# R7FA2E307 register map
Vendor: Renesas Electronics Corporation; Series: RA2; File version: 1.20.00
CPU: CM23 r1p0, little endian, MPU, no FPU, VTOR, 2 interrupt priority bits, 32 interrupts
Registers are 8-bit, read-write, reset 0x0 unless marked. A register's access mark holds for its fields unless they carry their own. Offsets are from the block's base; [hi:lo] are bit positions; {n}, {i} and the like mark numbered series.

## ADC120 — 12-bit A/D Converter
Base 0x4005C000
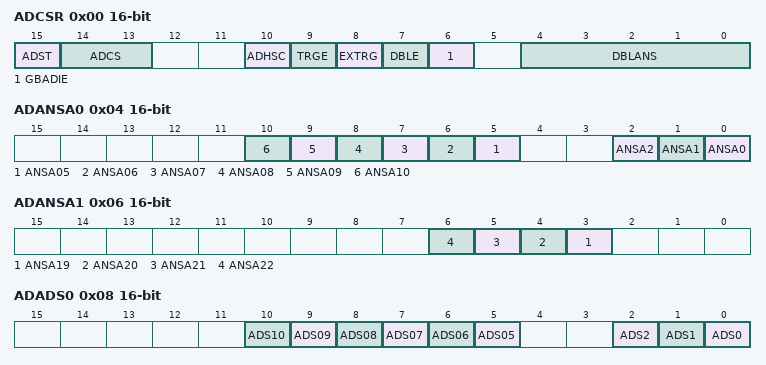
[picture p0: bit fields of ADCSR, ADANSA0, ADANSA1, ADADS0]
0x00 ADCSR 16-bit — A/D Control Register
  [15] ADST — A/D Conversion Start
  [14:13] ADCS — Scan Mode Select
  [10] ADHSC — A/D Conversion Mode Select
  [9] TRGE — Trigger Start Enable
  [8] EXTRG — Trigger Select
  [7] DBLE — Double Trigger Mode Select
  [6] GBADIE — Group B Scan End Interrupt and ELC Event Enable
  [4:0] DBLANS — Double Trigger Channel Select
0x04 ADANSA0 16-bit — A/D Channel Select Register A0
  [n] ANSA{n:02} (n=5..10) — A/D Conversion Channels Select
  [2] ANSA2 — A/D Conversion Channels Select
  [1] ANSA1 — A/D Conversion Channels Select
  [0] ANSA0 — A/D Conversion Channels Select
0x06 ADANSA1 16-bit — A/D Channel Select Register A1
  [n-16] ANSA{n} (n=19..22) — A/D Conversion Channels Select
0x08 ADADS0 16-bit — A/D,Converted Value Addition/Average Channel Select Register 0
  [n] ADS{n:02} (n=5..10) — A/D,Converted Value Addition/Average Channel Select
  [2] ADS2 — A/D,Converted Value Addition/Average Channel Select
  [1] ADS1 — A/D,Converted Value Addition/Average Channel Select
  [0] ADS0 — A/D,Converted Value Addition/Average Channel Select
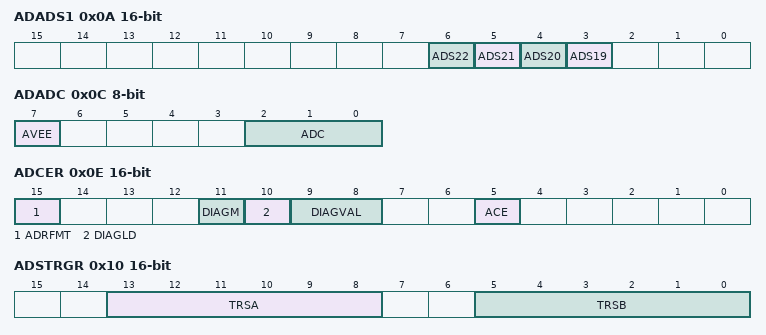
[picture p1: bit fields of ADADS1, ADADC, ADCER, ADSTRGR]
0x0A ADADS1 16-bit — A/D,Converted Value Addition/Average Channel Select Register 1
  [n-16] ADS{n} (n=19..22) — A/D,Converted Value Addition/Average Channel Select
0x0C ADADC — A/D,Converted Value Addition/Average Count Select Register
  [7] AVEE — Average Mode Select
  [2:0] ADC — Addition/Average Count Select
0x0E ADCER 16-bit — A/D Control Extended Register
  [15] ADRFMT — A/D Data Register Format Select
  [11] DIAGM — Self,Diagnosis Enable
  [10] DIAGLD — Self,Diagnosis Mode Select
  [9:8] DIAGVAL — Self,Diagnosis Conversion Voltage Select
  [5] ACE — A/D Data Register Automatic Clearing Enable
0x10 ADSTRGR 16-bit — A/D Conversion Start Trigger Select Register
  [13:8] TRSA — A/D Conversion Start Trigger Select
  [5:0] TRSB — A/D Conversion Start Trigger Select for Group B
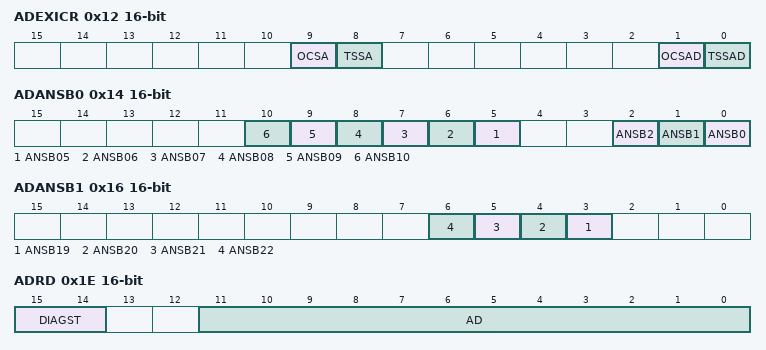
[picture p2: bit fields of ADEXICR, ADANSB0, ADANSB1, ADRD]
0x12 ADEXICR 16-bit — A/D Conversion Extended Input Control Registers
  [9] OCSA — Internal Reference Voltage A/D Conversion Select
  [8] TSSA — Temperature Sensor Output A/D Conversion Select
  [1] OCSAD — Internal Reference Voltage A/D,Converted Value Addition/Average Mode Select
  [0] TSSAD — Temperature Sensor Output A/D,Converted Value Addition/Average Mode Select
0x14 ADANSB0 16-bit — A/D Channel Select Register B0
  [n] ANSB{n:02} (n=5..10) — A/D Conversion Channels Select
  [2] ANSB2 — A/D Conversion Channels Select
  [1] ANSB1 — A/D Conversion Channels Select
  [0] ANSB0 — A/D Conversion Channels Select
0x16 ADANSB1 16-bit — A/D Channel Select Register B1
  [n-16] ANSB{n} (n=19..22) — A/D Conversion Channels Select
0x18 ADDBLDR 16-bit ro — A/D Data Duplexing Register
  [15:0] ADDBLDR — Converted Value 15 to 0
0x1A ADTSDR 16-bit ro — A/D Temperature Sensor Data Register
  [15:0] ADTSDR — Converted Value 15 to 0
0x1C ADOCDR 16-bit ro — A/D Internal Reference Voltage Data Register
  [15:0] ADOCDR — Converted Value 15 to 0
0x1E ADRD 16-bit ro — A/D Self,Diagnosis Data Register
  [15:14] DIAGST — Self,Diagnosis Status
  [11:0] AD — Converted Value 11 to 0
{0x20+2i} ADDR{i} (i=0..2) 16-bit ro — A/D Data Registers {i}
  [15:0] ADDR — Converted Value 15 to 0
{0x20+2i} ADDR{i}_1 (i=5..10) 16-bit ro — A/D Data Registers {i}
  [15:0] ADDR — Converted Value 15 to 0
{0x20+2i} ADDR{i}_2 (i=19..22) 16-bit ro — A/D Data Registers {i}
  [15:0] ADDR — Converted Value 15 to 0
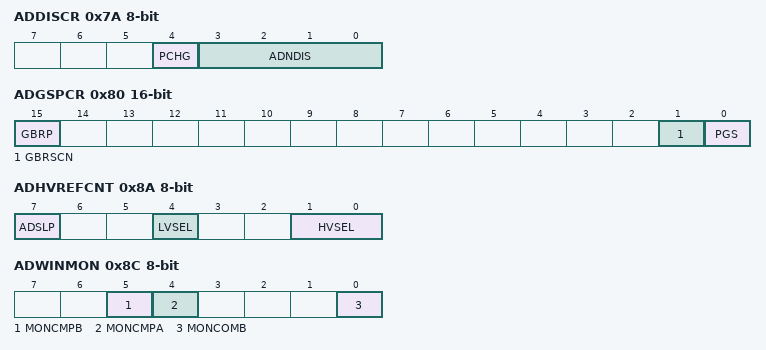
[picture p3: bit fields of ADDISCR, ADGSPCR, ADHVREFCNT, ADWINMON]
0x7A ADDISCR — A/D Disconnection Detection Control Register
  [4] PCHG — Precharge/discharge select
  [3:0] ADNDIS — Disconnection Detection Assist Setting
0x7E ADACSR — A/D Conversion Operation Mode Select Register
  [1] ADSAC — Successive Approximation Control Setting
0x80 ADGSPCR 16-bit — A/D Group Scan Priority Control Register
  [15] GBRP — Single Scan Continuous Start
  [1] GBRSCN — Lower,Priority Group Restart Setting
  [0] PGS — Group Priority Operation Setting
0x84 ADDBLDRA 16-bit ro — A/D Data Duplexing Register A
  [15:0] ADDBLDR — Converted Value 15 to 0
0x86 ADDBLDRB 16-bit ro — A/D Data Duplexing Register B
  [15:0] ADDBLDR — Converted Value 15 to 0
0x8A ADHVREFCNT — A/D High,Potential/Low,Potential Reference Voltage Control Register
  [7] ADSLP — Sleep
  [4] LVSEL — Low,Potential Reference Voltage Select
  [1:0] HVSEL — High,Potential Reference Voltage Select
0x8C ADWINMON ro — A/D Compare Function Window A/B Status Monitor Register
  [5] MONCMPB — Comparison Result Monitor B
  [4] MONCMPA — Comparison Result Monitor A
  [0] MONCOMB — Combination Result Monitor
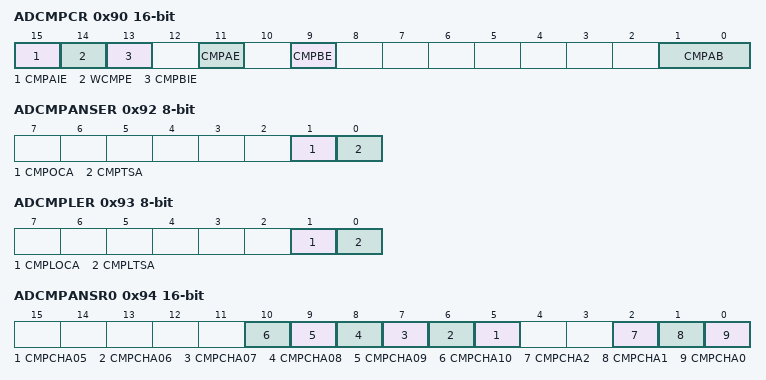
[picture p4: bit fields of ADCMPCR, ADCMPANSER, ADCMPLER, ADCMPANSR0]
0x90 ADCMPCR 16-bit — A/D Compare Function Control Register
  [15] CMPAIE — Compare A Interrupt Enable
  [14] WCMPE — Window Function Setting
  [13] CMPBIE — Compare B Interrupt Enable
  [11] CMPAE — Compare Window A Operation Enable
  [9] CMPBE — Compare Window B Operation Enable
  [1:0] CMPAB — Window A/B Composite Conditions Setting
0x92 ADCMPANSER — A/D Compare Function Window A Extended Input Select Register
  [1] CMPOCA — Internal Reference Voltage Compare Select
  [0] CMPTSA — Temperature Sensor Output Compare Select
0x93 ADCMPLER — A/D Compare Function Window A Extended Input Comparison Condition Setting Register
  [1] CMPLOCA — Compare Window A Internal Reference Voltage Comparison Condition Select
  [0] CMPLTSA — Compare Window A Temperature Sensor Output Comparison Condition Select
0x94 ADCMPANSR0 16-bit — A/D Compare Function Window A Channel Select Register 0
  [n] CMPCHA{n:02} (n=5..10) — Compare Window A Channel Select
  [2] CMPCHA2 — Compare Window A Channel Select
  [1] CMPCHA1 — Compare Window A Channel Select
  [0] CMPCHA0 — Compare Window A Channel Select
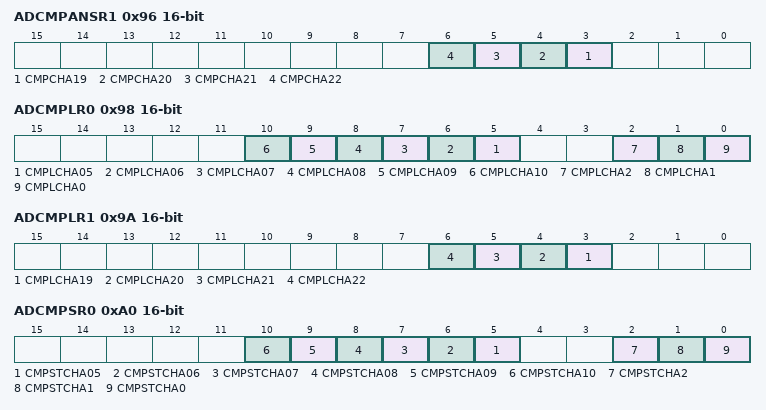
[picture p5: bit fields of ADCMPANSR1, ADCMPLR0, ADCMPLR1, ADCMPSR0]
0x96 ADCMPANSR1 16-bit — A/D Compare Function Window A Channel Select Register 1
  [n-16] CMPCHA{n} (n=19..22) — Compare Window A Channel Select
0x98 ADCMPLR0 16-bit — A/D Compare Function Window A Comparison Condition Setting Register 0
  [n] CMPLCHA{n:02} (n=5..10) — Compare Window A Comparison Condition Select
  [2] CMPLCHA2 — Compare Window A Comparison Condition Select
  [1] CMPLCHA1 — Compare Window A Comparison Condition Select
  [0] CMPLCHA0 — Compare Window A Comparison Condition Select
0x9A ADCMPLR1 16-bit — A/D Compare Function Window A Comparison Condition Setting Register 1
  [n-16] CMPLCHA{n} (n=19..22) — Compare Window A Comparison Condition Select
{0x9C+2i} ADCMPDR{i} (i=0..1) 16-bit — A/D Compare Function Window A Lower,Side/Upper,Side Level Setting Register
0xA0 ADCMPSR0 16-bit — A/D Compare Function Window A Channel Status Register 0
  [n] CMPSTCHA{n:02} (n=5..10) — Compare Window A Flag
  [2] CMPSTCHA2 — Compare Window A Flag
  [1] CMPSTCHA1 — Compare Window A Flag
  [0] CMPSTCHA0 — Compare Window A Flag
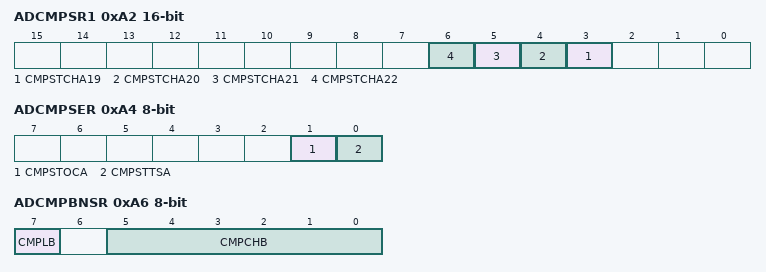
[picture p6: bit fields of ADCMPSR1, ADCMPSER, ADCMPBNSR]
0xA2 ADCMPSR1 16-bit — A/D Compare Function Window A Channel Status Register1
  [n-16] CMPSTCHA{n} (n=19..22) — Compare Window A Flag
0xA4 ADCMPSER — A/D Compare Function Window A Extended Input Channel Status Register
  [1] CMPSTOCA — Compare Window A Internal Reference Voltage Compare Flag
  [0] CMPSTTSA — Compare Window A Temperature Sensor Output Compare Flag
0xA6 ADCMPBNSR — A/D Compare Function Window B Channel Select Register
  [7] CMPLB — Compare Window B Comparison Condition Setting
  [5:0] CMPCHB — Compare Window B Channel Select
0xA8 ADWINLLB 16-bit — A/D Compare Function Window B Lower,Side/Upper,Side Level Setting Register
0xAA ADWINULB 16-bit — A/D Compare Function Window B Lower,Side/Upper,Side Level Setting Register
0xAC ADCMPBSR — A/D Compare Function Window B Status Register
  [0] CMPSTB — Compare Window B Flag
0xDD ADSSTRL reset 0xD — A/D Sampling State Register
  [7:0] SST — Sampling Time Setting
0xDE ADSSTRT reset 0xD — A/D Sampling State Register
  [7:0] SST — Sampling Time Setting
0xDF ADSSTRO reset 0xD — A/D Sampling State Register
  [7:0] SST — Sampling Time Setting
{0xE0+i} ADSSTR{i} (i=0..2) reset 0xD — A/D Sampling State Register
  [7:0] SST — Sampling Time Setting
{0xE0+i} ADSSTR{i}_1 (i=5..10) reset 0xD — A/D Sampling State Register
  [7:0] SST — Sampling Time Setting
